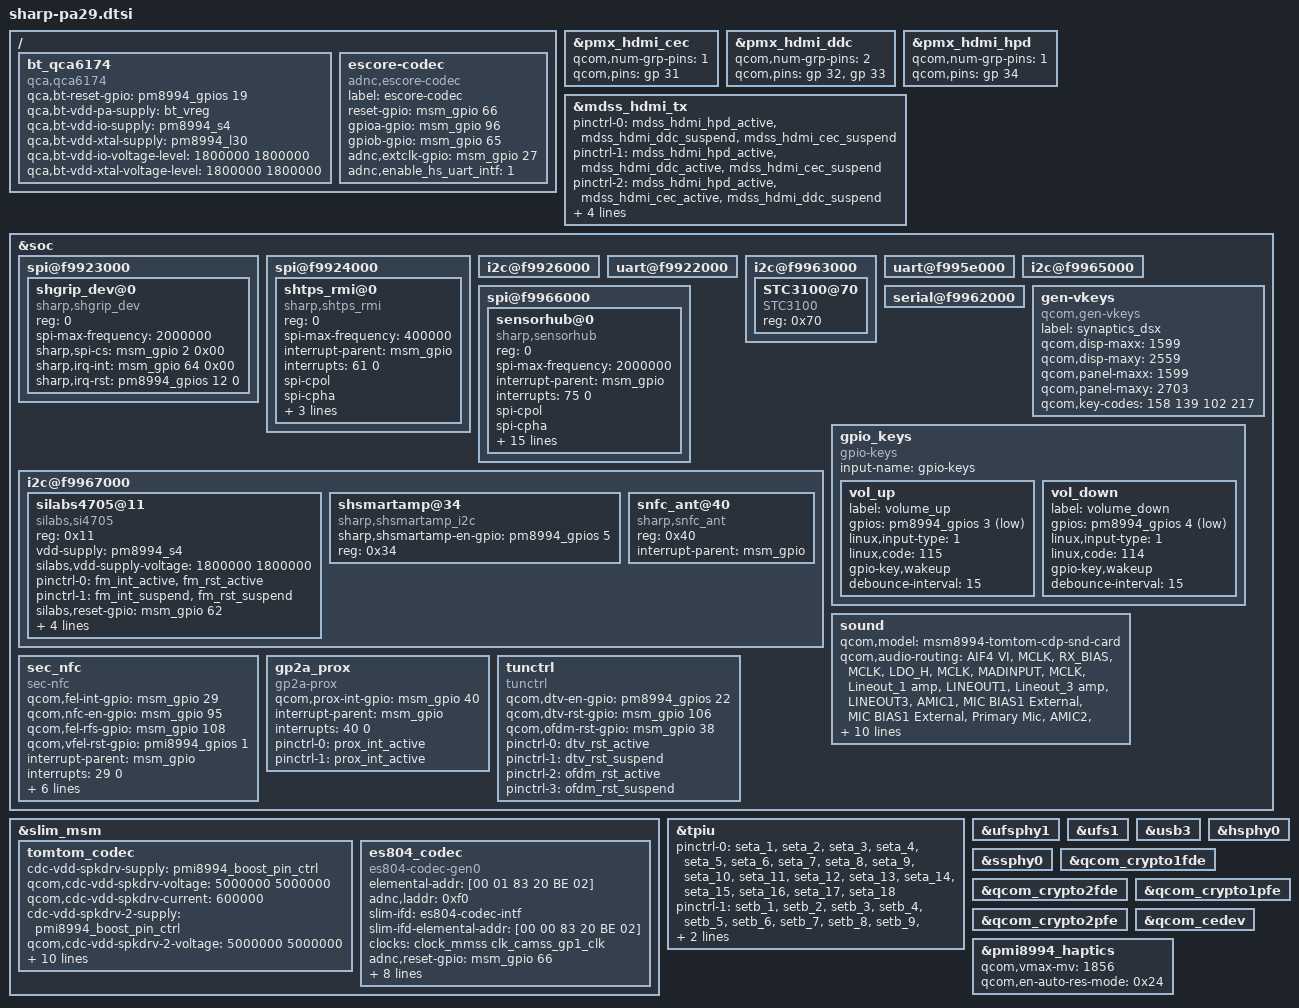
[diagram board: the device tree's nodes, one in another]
/* Copyright (c) 2014-2015, The Linux Foundation. All rights reserved.
 *
 * This program is free software; you can redistribute it and/or modify
 * it under the terms of the GNU General Public License version 2 and
 * only version 2 as published by the Free Software Foundation.
 *
 * This program is distributed in the hope that it will be useful,
 * but WITHOUT ANY WARRANTY; without even the implied warranty of
 * MERCHANTABILITY or FITNESS FOR A PARTICULAR PURPOSE.  See the
 * GNU General Public License for more details.
 */

#include "msm8994-pinctrl.dtsi"
/* SH_CAMERA_DRIVER-> */
//#include "msm8994-camera-sensor-cdp.dtsi"
#include "sharp-pa29-camera-sensor.dtsi"
/* SH_CAMERA_DRIVER<- */
#include "sharp_pinctrl/sharp-pinctrl-pa29.dtsi"

/ {
	bt_qca6174 {
		compatible = "qca,qca6174";
		qca,bt-reset-gpio = <&pm8994_gpios 19 0>; /* BT_EN */
		qca,bt-vdd-pa-supply = <&bt_vreg>;
		qca,bt-vdd-io-supply = <&pm8994_s4>;
		qca,bt-vdd-xtal-supply = <&pm8994_l30>;
		qca,bt-vdd-io-voltage-level = <1800000 1800000>;
		qca,bt-vdd-xtal-voltage-level = <1800000 1800000>;
	};

/* SH_AUDIO_DRIVER -> */ /*14-061*/
	escore-codec {
		compatible = "adnc,escore-codec";
		label = "escore-codec";
		reset-gpio = <&msm_gpio 66 0>;
		gpioa-gpio = <&msm_gpio 96 0>;
		gpiob-gpio = <&msm_gpio 65 0>;
		adnc,extclk-gpio = <&msm_gpio 27 0>;
		adnc,enable_hs_uart_intf = <1>;
	};
/* SH_AUDIO_DRIVER <- */ /*14-061*/
};

#include "sharp-pa29-shdisp.dtsi"

&pmx_hdmi_cec {
	qcom,num-grp-pins = <1>;
	qcom,pins = <&gp 31>;
};

&pmx_hdmi_ddc {
	qcom,num-grp-pins = <2>;
	qcom,pins = <&gp 32>, <&gp 33>;
};

&pmx_hdmi_hpd {
	qcom,num-grp-pins = <1>;
	qcom,pins = <&gp 34>;
};

&mdss_hdmi_tx {
	pinctrl-names = "hdmi_hpd_active", "hdmi_ddc_active",
				"hdmi_cec_active", "hdmi_active",
				"hdmi_sleep";
	pinctrl-0 = <&mdss_hdmi_hpd_active &mdss_hdmi_ddc_suspend
						&mdss_hdmi_cec_suspend>;
	pinctrl-1 = <&mdss_hdmi_hpd_active &mdss_hdmi_ddc_active
						&mdss_hdmi_cec_suspend>;
	pinctrl-2 = <&mdss_hdmi_hpd_active &mdss_hdmi_cec_active
						&mdss_hdmi_ddc_suspend>;
	pinctrl-3 = <&mdss_hdmi_hpd_active &mdss_hdmi_ddc_active
						&mdss_hdmi_cec_active>;
	pinctrl-4 = <&mdss_hdmi_hpd_suspend &mdss_hdmi_ddc_suspend
						&mdss_hdmi_cec_suspend>;
};

&soc {
	/*****************************************/
	/*  BLSP1                                */
	/*****************************************/
	/*---------------------*/
	/* BLSP1 QUP0(BLSP#1)  */
	/*---------------------*/
	spi@f9923000 {
		status = "ok";
		shgrip_dev@0 {
			status = "ok";
			compatible = "sharp,shgrip_dev";
			reg = <0>;
			spi-max-frequency = <2000000>;
			sharp,spi-cs  = <&msm_gpio 2 0x00>;
			sharp,irq-int = <&msm_gpio 64 0x00>;
			sharp,irq-rst = <&pm8994_gpios 12 0>;
		};
	};
	
	/*---------------------*/
	/* BLSP1 QUP1(BLSP#2)  */
	/*---------------------*/
	spi@f9924000 {
		status = "ok";
		shtps_rmi@0 {
			status = "ok";
			compatible = "sharp,shtps_rmi";
			reg = <0>;
			spi-max-frequency = <400000>;
			interrupt-parent = <&msm_gpio>;
			interrupts = <61 0>;
			spi-cpol;
			spi-cpha;

			/* user defined property */
			shtps_rmi,rst_pin = <&msm_gpio 60 0>;
			shtps_rmi,vdd_3_0V = <&pm8994_l21>;
			shtps_rmi,tpin = <&msm_gpio 63 0>;
		};
	};
	
	/*---------------------*/
	/* BLSP1 QUP2(BLSP#3)  */
	/*---------------------*/
	
	/*---------------------*/
	/* BLSP1 QUP3(BLSP#4)  */
	/*---------------------*/
	i2c@f9926000 {
		status = "ok";
	};
	
	/*---------------------*/
	/* BLSP1 QUP4(BLSP#5)  */
	/*---------------------*/
	
	/*---------------------*/
	/* BLSP1 QUP5(BLSP#6)  */
	/*---------------------*/
	uart@f9922000 {
		status = "ok";
	};
	
	/*****************************************/
	/*  BLSP2                                */
	/*****************************************/
	/*---------------------*/
	/* BLSP2 QUP0(BLSP#7)  */
	/*---------------------*/
	i2c@f9963000 {
		status = "ok";
		STC3100@70 {
			status = "ok";
			compatible = "STC3100";
			reg = <0x70>;
		};
	};
	
	/*---------------------*/
	/* BLSP2 QUP1(BLSP#8)  */
	/*---------------------*/
	uart@f995e000 {
		status = "ok";
	};
	
	/*---------------------*/
	/* BLSP2 QUP2(BLSP#9)  */
	/*---------------------*/
	i2c@f9965000 {
		status = "ok";
	};
	
	/*---------------------*/
	/* BLSP2 QUP3(BLSP#10)  */
	/*---------------------*/
	spi@f9966000 {
		status = "ok";
		sensorhub@0 {
			status = "ok";
			compatible = "sharp,sensorhub";
			reg = <0>;
			spi-max-frequency = <2000000>;
			interrupt-parent = <&msm_gpio>;
			interrupts = <75 0>;
			spi-cpol;
			spi-cpha;
			qcom,shub-gpio-reset = <&msm_gpio 93 0>;
			qcom,shub-gpio-brmp = <&msm_gpio 94 0>;
			qcom,shub-gpio-int0 = <&msm_gpio 75 0>;
			qcom,shub-gpio-int1 = <&msm_gpio 76 0>;
			pinctrl-names = "shub_reset_active","shub_reset_suspend",
							"shub_int0_active","shub_int0_suspend",
							"shub_int1_active","shub_int1_suspend",
							"shub_brmp_active","shub_brmp_suspend";
			pinctrl-0 = <&shub_reset_active>;
			pinctrl-1 = <&shub_reset_suspend>;
			pinctrl-2 = <&shub_int0_active>;
			pinctrl-3 = <&shub_int0_suspend>;
			pinctrl-4 = <&shub_int1_active>;
			pinctrl-5 = <&shub_int1_suspend>;
			pinctrl-6 = <&shub_brmp_active>;
			pinctrl-7 = <&shub_brmp_suspend>;
			shub,shub_acc_axis_val = <1>;
			shub,shub_gyro_axis_val = <1>;
			shub,shub_mag_axis_val = <0>;
		};
	};
	
	/*---------------------*/
	/* BLSP2 QUP4(BLSP#11)  */
	/*---------------------*/
	i2c@f9967000 {
		status = "ok";
		silabs4705@11 { /* SiLabs FM chip, slave id 0x11*/
			status = "ok";
			compatible = "silabs,si4705";
			reg = <0x11>;
			vdd-supply = <&pm8994_s4>;
			silabs,vdd-supply-voltage = <1800000 1800000>;
			pinctrl-names = "pmx_fm_active","pmx_fm_suspend";
			pinctrl-0 = <&fm_int_active &fm_rst_active>;
			pinctrl-1 = <&fm_int_suspend &fm_rst_suspend>;
			silabs,reset-gpio = <&msm_gpio 62 0>;
			silabs,int-gpio = <&msm_gpio 9 0>;
			silabs,status-gpio = <&msm_gpio 11 0>;
			interrupt-parent = <&msm_gpio>;
			interrupts = <9 2>;
			interrupt-names = "silabs_fm_int";
		};
/* SH_AUDIO_DRIVER -> */ /*14-002*/
		shsmartamp@34 {
			status = "ok";
			compatible = "sharp,shsmartamp_i2c";
			sharp,shsmartamp-en-gpio = <&pm8994_gpios 5 0>;
			reg = <0x34>;
		};
/* SH_AUDIO_DRIVER <- */ /*14-002*/

        snfc_ant@40 {
            status = "ok";
            compatible = "sharp,snfc_ant";
            reg = <0x40>;
            interrupt-parent = <&msm_gpio>;
        };

	};
	
	/*---------------------*/
	/* BLSP2 QUP5(BLSP#12)  */
	/*---------------------*/
	serial@f9962000 {
		status = "ok";
	};

	gen-vkeys {
		compatible = "qcom,gen-vkeys";
		label = "synaptics_dsx";
		qcom,disp-maxx = <1599>;
		qcom,disp-maxy = <2559>;
		qcom,panel-maxx = <1599>;
		qcom,panel-maxy = <2703>;
		qcom,key-codes = <158 139 102 217>;
	};

	gpio_keys {
		compatible = "gpio-keys";
		input-name = "gpio-keys";

		vol_up {
			label = "volume_up";
			gpios = <&pm8994_gpios 3 0x1>;
			linux,input-type = <1>;
			linux,code = <115>;
			gpio-key,wakeup;
			debounce-interval = <15>;
		};

//		cam_snapshot {
//			label = "cam_snapshot";
//			gpios = <&pm8994_gpios 4 0x1>;
//			linux,input-type = <1>;
//			linux,code = <766>;
//			gpio-key,wakeup;
//			debounce-interval = <15>;
//		};

		vol_down {
			label = "volume_down";
			gpios = <&pm8994_gpios 4 0x1>;
			linux,input-type = <1>;
			linux,code = <114>;
			gpio-key,wakeup;
			debounce-interval = <15>;
		};

//		cam_focus {
//			label = "cam_focus";
//			gpios = <&pm8994_gpios 5 0x1>;
//			linux,input-type = <1>;
//			linux,code = <528>;
//			gpio-key,wakeup;
//			debounce-interval = <15>;
//		};


	};

	sound {
		qcom,model = "msm8994-tomtom-cdp-snd-card";
/* => SH_AUDIO_DRIVER 14-001 14-002 */
		qcom,audio-routing =
			"AIF4 VI", "MCLK",
			"RX_BIAS", "MCLK",
			"LDO_H", "MCLK",
			"MADINPUT", "MCLK",
			"Lineout_1 amp", "LINEOUT1",
			"Lineout_3 amp", "LINEOUT3",
			"AMIC1", "MIC BIAS1 External",
			"MIC BIAS1 External", "Primary Mic",
			"AMIC2", "MIC BIAS2 External",
			"MIC BIAS2 External", "Headset Mic",
			"AMIC3", "MIC BIAS3 External",
			"MIC BIAS3 External", "Secondary Mic",
			"AMIC5", "MIC BIAS4 External",
			"MIC BIAS4 External", "Tertiary Mic";
/* <= SH_AUDIO_DRIVER 14-001 14-002 */
		qcom,cdc-micbias2-headset-only;
/* => SH_AUDIO_DRIVER 14-004 */
//		qcom,us-euro-gpios = <&pm8994_mpps 2 0>;
//		qcom,mbhc-audio-jack-type = "6-pole-jack";
		qcom,mbhc-audio-jack-type = "4-pole-jack";
/* <= SH_AUDIO_DRIVER 14-004 */
/* => SH_AUDIO_DRIVER 14-060 */
//		qcom,hdmi-audio-rx;
/* <= SH_AUDIO_DRIVER 14-060 */
		asoc-codec = <&stub_codec>, <&hdmi_audio>;
		asoc-codec-names = "msm-stub-codec.1", "msm-hdmi-audio-codec-rx";
	};

	sec_nfc {
		compatible = "sec-nfc";
		qcom,fel-int-gpio  = <&msm_gpio 29 0x00>;
		qcom,nfc-en-gpio   = <&msm_gpio 95 0x00>;
		qcom,fel-rfs-gpio  = <&msm_gpio 108 0x00>;
		qcom,vfel-rst-gpio = <&pmi8994_gpios 1 0x00>;
		interrupt-parent  = <&msm_gpio>;
		interrupts = <29 0>;
		interrupt-names = "fel_int_n";
		pinctrl-names = "fel_int_active","fel_int_suspend",
						"nfc_en_active","nfc_en_suspend",
						"fel_rfs_active","fel_rfs_suspend";
		pinctrl-0 = <&fel_int_active>;
		pinctrl-1 = <&fel_int_suspend>;
		pinctrl-2 = <&nfc_en_active>;
		pinctrl-3 = <&nfc_en_suspend>;
		pinctrl-4 = <&fel_rfs_active>;
		pinctrl-5 = <&fel_rfs_suspend>;
	};

    gp2a_prox {
		compatible = "gp2a-prox";
		qcom,prox-int-gpio  = <&msm_gpio 40 0x00>;
		interrupt-parent  = <&msm_gpio>;
		interrupts = <40 0>;
		interrupt-names = "prox_int";
		pinctrl-names = "prox_int_active","prox_int_suspend";
		pinctrl-0 = <&prox_int_active>;
		pinctrl-1 = <&prox_int_active>;
	};

    tunctrl {
        compatible = "tunctrl";
		qcom,dtv-en-gpio = <&pm8994_gpios 22 0>;
		qcom,dtv-rst-gpio  = <&msm_gpio 106 0x00>;
		qcom,ofdm-rst-gpio  = <&msm_gpio 38 0x00>;
		pinctrl-names = "dtv_rst_active","dtv_rst_suspend",
						"ofdm_rst_active","ofdm_rst_suspend";
		pinctrl-0 = <&dtv_rst_active>;
		pinctrl-1 = <&dtv_rst_suspend>;
		pinctrl-2 = <&ofdm_rst_active>;
		pinctrl-3 = <&ofdm_rst_suspend>;
    };

};

&slim_msm {
	tomtom_codec {
		qcom,cdc-micbias1-ext-cap;
		qcom,cdc-micbias3-ext-cap;
		qcom,cdc-micbias4-ext-cap;
		cdc-vdd-spkdrv-supply = <&pmi8994_boost_pin_ctrl>;
		qcom,cdc-vdd-spkdrv-voltage = <5000000 5000000>;
		qcom,cdc-vdd-spkdrv-current = <600000>;

		cdc-vdd-spkdrv-2-supply = <&pmi8994_boost_pin_ctrl>;
		qcom,cdc-vdd-spkdrv-2-voltage = <5000000 5000000>;
		qcom,cdc-vdd-spkdrv-2-current = <600000>;

		qcom,cdc-on-demand-supplies = "cdc-vdd-spkdrv",
					      "cdc-vdd-spkdrv-2";
/* => SH_AUDIO_DRIVER 14-003 */
		qcom,cdc-micbias-cfilt1-mv = <2700>;
		qcom,cdc-micbias-cfilt2-mv = <2700>;
		qcom,cdc-micbias1-cfilt-sel = <0x0>;
		qcom,cdc-micbias2-cfilt-sel = <0x1>;
		qcom,cdc-micbias3-cfilt-sel = <0x0>;
		qcom,cdc-micbias4-cfilt-sel = <0x0>;
		/delete-property/ qcom,cdc-micbias1-ext-cap;
		/delete-property/ qcom,cdc-micbias2-ext-cap;
		/delete-property/ qcom,cdc-micbias3-ext-cap;
		/delete-property/ qcom,cdc-micbias4-ext-cap;
/* <= SH_AUDIO_DRIVER 14-003 */
/* => SH_AUDIO_DRIVER 14-062 */
		qcom,cdc-mad-dmic-rate = <4800000>;
/* <= SH_AUDIO_DRIVER 14-062 */
	};
/* SH_AUDIO_DRIVER -> */ /*14-061*/
	es804_codec {
		compatible = "es804-codec-gen0";
		elemental-addr = [00 01 83 20 BE 02];
		adnc,laddr = <0xf0>;
		slim-ifd = "es804-codec-intf";
		slim-ifd-elemental-addr = [00 00 83 20 BE 02];

		clocks = <&clock_mmss clk_camss_gp1_clk>;
		clock-names = "aud_cam_clk";
		adnc,reset-gpio = <&msm_gpio 66 0>;
		adnc,gpioa-gpio = <&msm_gpio 96 0>;
		adnc,gpiob-gpio = <&msm_gpio 65 0>;
		adnc,extclk-gpio = <&msm_gpio 27 0>;

		adnc,enable_hs_uart_intf = <1>;

		pinctrl-names = "aud_active","aud_suspend";
		pinctrl-0 = <&sharp_pinctrl_aud_clk_active &aud_reset_active &aud_intb_active>;
		pinctrl-1 = <&sharp_pinctrl_aud_clk_suspend &aud_reset_suspend &aud_intb_suspend>;
	};
/* SH_AUDIO_DRIVER <- */ /*14-061*/
};

/* CoreSight */
&tpiu {
	pinctrl-names = "seta-pctrl", "setb-pctrl";
	pinctrl-0 = <&seta_1 &seta_2 &seta_3 &seta_4 &seta_5 &seta_6 &seta_7
		     &seta_8 &seta_9 &seta_10 &seta_11 &seta_12 &seta_13
		     &seta_14 &seta_15 &seta_16 &seta_17 &seta_18>;
	pinctrl-1 = <&setb_1 &setb_2 &setb_3 &setb_4 &setb_5 &setb_6 &setb_7
		     &setb_8 &setb_9 &setb_10 &setb_11 &setb_12 &setb_13
		     &setb_14 &setb_15 &setb_16 &setb_17 &setb_18>;
};

&ufsphy1 {
	status = "ok";
};

&ufs1 {
	status = "ok";
};

&usb3 {
	status = "ok";
};

&hsphy0 {
	status = "ok";
};

&ssphy0 {
	status = "ok";
};

&qcom_crypto1fde {
	status = "okay";
};

&qcom_crypto2fde {
	status = "okay";
};

&qcom_crypto1pfe {
	status = "okay";
};

&qcom_crypto2pfe {
	status = "okay";
};

&qcom_cedev {
	status = "okay";
};

&pmi8994_haptics {
	status = "okay";
	qcom,vmax-mv = <1856>;
	qcom,en-auto-res-mode = <0x24>;
};

#include "sharp-pa29-pm8994.dtsi"
#include "sharp-pa29-pmi8994.dtsi"
